# NANO100AN_v1 register map
File version: 1.0
Registers are 32-bit, read-write, reset 0x0 unless marked. A register's access mark holds for its fields unless they carry their own. Offsets are from the block's base; [hi:lo] are bit positions; {n}, {i} and the like mark numbered series.

## CLK — CLK Register Map
Base 0x50000200
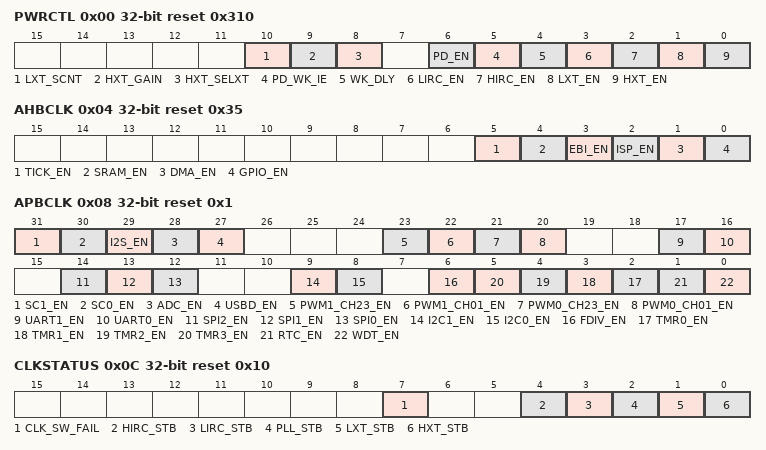
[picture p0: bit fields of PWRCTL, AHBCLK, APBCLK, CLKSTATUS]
0x00 PWRCTL reset 0x310 (reset mask 0xFFFFFFF0) — System Power Down Control Register
  [10] LXT_SCNT — LXT Stable Time Control. This is a protected register. Please refer to open lock sequence to program it.
    0=Delay 4096 LXT before LXT output; 1=Delay 8192 LXT before LXT output
  [9] HXT_GAIN — HXT Gain Control Bit. This is a protected register. Please refer to open lock sequence to program it. Gain control is used to enlarge the gain of crystal to make sure crystal wok normally. If gain control is enabled, crystal will consume more power than gain control off.
    0=Gain control Disabled. It means HXT gain is always high; 1=Gain control Enabled. HXT gain will be high lasting 2ms then low. This is for power saving
  [8] HXT_SELXT — HXT SELXT. This is a protected register. Please refer to open lock sequence to program it.
    0=High frequency crystal loop back path Disabled. It is used for external oscillator; 1=High frequency crystal loop back path Enabled. It is used for external crystal
  [6] PD_EN — Chip Power-Down Mode Enable Bit. This is a protected register. Please refer to open lock sequence to program it. When CPU sets this bit, the chip power down is enabled and chip will not enter Power-down mode until CPU sleep mode is also active. When chip wakes up from Power-down mode, this bit will be auto cleared. When chip is in Power-down mode, the LDO, HXT and HIRC will be disabled, but LXT and LIRC are not controlled by Power-down mode. When power down, the PLL and system clock (CPU, HCLKx and PCLKx) are also disabled no matter the Clock Source selection. Peripheral clocks are not controlled by this bit, if peripheral Clock Source is from LXT or LIRC. In Power-down mode, flash macro power is ON. NOTE: It inhibits to set both PD_EN and DPD_EN high.
    0=Chip operated in Normal mode; 1=Chip power down Enabled
  [5] PD_WK_IE — Power-Down Mode Wake-Up Interrupt Enable. This is a protected register. Please refer to open lock sequence to program it. PD_WK_INT will be set if both PD_WK_IS (PD_WK_IS[0]) and PD_WK_IE (PWRCTL[5]) are high.
    0=Disabled; 1=Enabled
  [4] WK_DLY — Wake-Up Delay Counter Enable. This is a protected register. Please refer to open lock sequence to program it. When chip wakes up from Power-down mode, the clock control will delay 4096 clock cycles to wait HXT stable or 16 clock cycles to wait HIRC stable.
    0=Delay clock cycle delay Disabled; 1=Delay clock cycle delay Enabled
  [3] LIRC_EN — LIRC Control. This is a protected register. Please refer to open lock sequence to program it. LIRC is enabled by default.
    0=Disabled; 1=Enabled
  [2] HIRC_EN — HIRC Control. This is a protected register. Please refer to open lock sequence to program it. HIRC is enabled by default.
    0=Disabled; 1=Enabled
  [1] LXT_EN — LXT Control. This is a protected register. Please refer to open lock sequence to program it. LXT is disabled by default.
    0=Disabled; 1=Enabled
  [0] HXT_EN — HXT Control. This is a protected register. Please refer to open lock sequence to program it. The bit default value is set by flash controller user configuration register config0 [26]. HXT is disabled by default.
    0=Disabled; 1=Enabled
0x04 AHBCLK reset 0x35 — AHB Devices Clock Enable Control Register
  [all] fields
    0=Disabled; 1=Enabled
  [5] TICK_EN — System Tick Clock Enable
  [4] SRAM_EN — SRAM Controller Clock Enable
  [3] EBI_EN — EBI Controller Clock Enable
  [2] ISP_EN — Flash ISP Controller Clock Enable
  [1] DMA_EN — DMA Controller Clock Enable
  [0] GPIO_EN — GPIO Controller Clock Enable
0x08 APBCLK reset 0x1 — APB Devices Clock Enable Control Register
  [all] fields
    0=Disabled; 1=Enabled
  [31] SC1_EN — SmartCard 1 Clock Enable Control
  [30] SC0_EN — SmartCard 0 Clock Enable Control
  [29] I2S_EN — I2S Clock Enable Control
  [28] ADC_EN — Analog-Digital-Converter (ADC) Clock Enable Control
  [27] USBD_EN — USB FS Device Controller Clock Enable Control
  [23] PWM1_CH23_EN — PWM1 Channel 2 And Channel 3 Clock Enable Control
  [22] PWM1_CH01_EN — PWM1 Channel 0 And Channel 1 Clock Enable Control
  [21] PWM0_CH23_EN — PWM0 Channel 2 And Channel 3 Clock Enable Control
  [20] PWM0_CH01_EN — PWM0 Channel 0 And Channel 1Clock Enable Control
  [17] UART1_EN — UART1 Clock Enable Control
  [16] UART0_EN — UART0 Clock Enable Control
  [14] SPI2_EN — SPI2 Clock Enable Control
  [13] SPI1_EN — SPI1 Clock Enable Control
  [12] SPI0_EN — SPI0 Clock Enable Control
  [9] I2C1_EN — I2C1 Clock Enable Control
  [8] I2C0_EN — I2C0 Clock Enable Control
  [6] FDIV_EN — Frequency Divider Output Clock Enable Control
  [n+2] TMR{n}_EN (n=0..3) — Timer{n} Clock Enable Control
  [1] RTC_EN — Real-Time-Clock Clock Enable Control. This bit is used to control the RTC APB clock only, The RTC engine Clock Source is from LXT.
  [0] WDT_EN — Watch-Dog Timer Clock Enable Control. This is a protected register. Please refer to open lock sequence to program it. This bit is used to control the WDT APB clock only, The WDT engine Clock Source is from LIRC.
0x0C CLKSTATUS ro reset 0x10 (reset mask 0xFFFFFFF0) — Clock Status Monitor Register
  [7] CLK_SW_FAIL — Clock Switch Fail Flag. This bit will be set when target switch Clock Source is not stable. This bit is write 1 clear
    0=Clock switch success; 1=Clock switch fail
  [4] HIRC_STB — HIRC Clock Source Stable Flag
    0=HIRC clock is not stable or not enable; 1=HIRC clock is stable
  [3] LIRC_STB — LIRC Clock Source Stable Flag
    0=LIRC clock is not stable or not enable; 1=LIRC clock is stable
  [2] PLL_STB — PLL Clock Source Stable Flag
    0=PLL clock is not stable or not enable; 1=PLL clock is stable
  [1] LXT_STB — LEXT Clock Source Stable Flag
    0=LXT clock is not stable or not enable; 1=LXT clock is stable
  [0] HXT_STB — HEXT Clock Source Stable Flag
    0=HXT clock is not stable or not enable; 1=HXT clock is stable
0x10 CLKSEL0 (reset mask 0xFFFFFFF0) — Clock Source Select Control Register 0
  [2:0] HCLK_S — HCLK Clock Source Selection
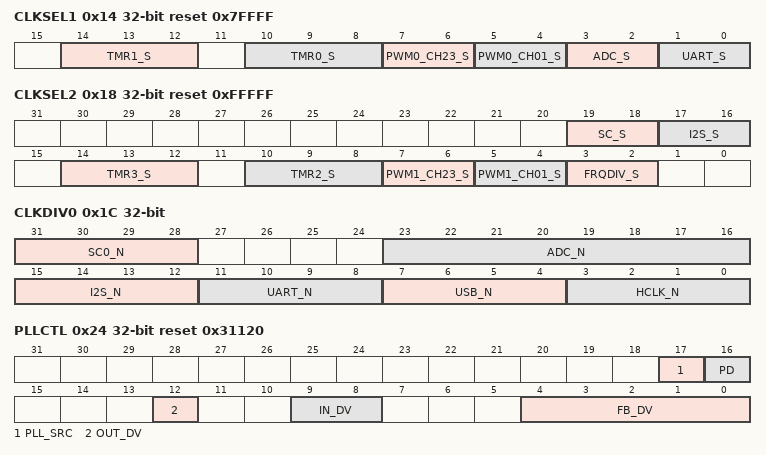
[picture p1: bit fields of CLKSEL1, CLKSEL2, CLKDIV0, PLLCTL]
0x14 CLKSEL1 reset 0x7FFFF — Clock Source Select Control Register 1
  [14:12] TMR1_S — TIMER 1 Clock Source Selection
  [10:8] TMR0_S — TIMER 0 Clock Source Selection
  [7:6] PWM0_CH23_S — PWM0 Channel 2 And Channel 3 Clock Source Selection
  [5:4] PWM0_CH01_S — PWM0 Channel 0 And Channel 1 Clock Source Selection
  [3:2] ADC_S — ADC Clock Source Selection
  [1:0] UART_S — UART 0/1 Clock Source Selection (UART0 And UART1 Use The Same Clock Source Selection)
0x18 CLKSEL2 reset 0xFFFFF — Clock Source Select Control Register 2
  [19:18] SC_S — SC Clock Source Selection
  [17:16] I2S_S — I2S Clock Source Selection
  [14:12] TMR3_S — TIMER 3 Clock Source Selection
  [10:8] TMR2_S — TIMER 2 Clock Source Selection
  [7:6] PWM1_CH23_S — PWM1 Channel 2 And Channel 2 Clock Source Selection
  [5:4] PWM1_CH01_S — PWM1 Channel 0 And Channel 1 Clock Source Selection
  [3:2] FRQDIV_S — Clock Divider Clock Source Selection
0x1C CLKDIV0 — Clock Divider Number Register 0
  [31:28] SC0_N — SC 0 Clock Divide Number From SC 0 Clock Source
  [23:16] ADC_N — ADC Clock Divide Number From ADC Clock Source
  [15:12] I2S_N — I2S Clock Divide Number From I2S Clock Source
  [11:8] UART_N — UART Clock Divide Number From UART Clock Source
  [7:4] USB_N — USB Clock Divide Number From PLL Clock
  [3:0] HCLK_N — HCLK Clock Divide Number From HCLK Clock Source
0x20 CLKDIV1 — Clock Divider Number Register 1
  [3:0] SC1_N — SC 1 Clock Divide Number From SC 1 Clock Source
0x24 PLLCTL reset 0x31120 — PLL Control Register
  [17] PLL_SRC — PLL Source Clock Select
    0=PLL source clock from HXT; 1=PLL source clock from HIRC
  [16] PD — Power-Down Mode. If set the PD_EN(PWRCTL[6]) "1" , the PLL will enter Power-down mode too
    0=PLL is in normal mode; 1=PLL is in power-down mode (default)
  [12] OUT_DV — PLL Output Divider Control Pins. Refer to the formulas below the table.
  [9:8] IN_DV — PLL Input Divider Control Pins. Refer to the formulas below the table.
  [4:0] FB_DV — PLL Feedback Divider Control Pins. Refer to the formulas below the table. The range of FB_DV is from 0 to 63.
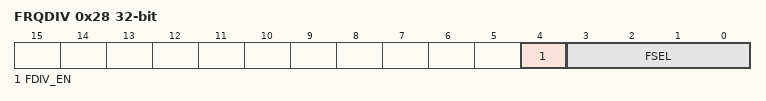
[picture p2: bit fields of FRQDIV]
0x28 FRQDIV — Frequency Divider Control Register
  [4] FDIV_EN — Frequency Divider Enable Bit
    0=Frequency Divider Disabled; 1=Frequency Divider Enabled
  [3:0] FSEL — Divider Output Frequency Selection Bits. The formula of output frequency is. Where Fin is the input clock frequency, Fout is the frequency of divider output clock and N is the 4-bit value of FSEL(FRQDIV[3:0]).
0x30 PD_WK_IS ro — Power-down Wake-up Interrupt Status Register
  [0] PD_WK_IS — Wake-Up Interrupt Sstatus In Chip Power-Down Mode. This bit indicates that some event resumes chip from Power-down mode. The status is set if external interrupts, UART, GPIO, RTC, USB, SPI, Timer, WDT, and BOD wake-up occurred. Write 1 to clear this bit.
